# USCI_A1__SPI_Mode_2 register map
Vendor: Texas Instruments
Peripheral module from a debugger description file (folder msp430).
Registers are 8-bit, access not given, no defined reset value unless marked. A register's access mark holds for its fields unless they carry their own. Offsets are as the file gives them; lines under a group give offsets from that group; [hi:lo] are bit positions; {n}, {i} and the like mark numbered series; 'fields as' and 'values as' point back to an identical list; <NAME> marks a mode.

## USCI_A1_SPI_Mode
0x600 UCA1CTLW0__SPI 16-bit — USCI A1 Control Word Register 0
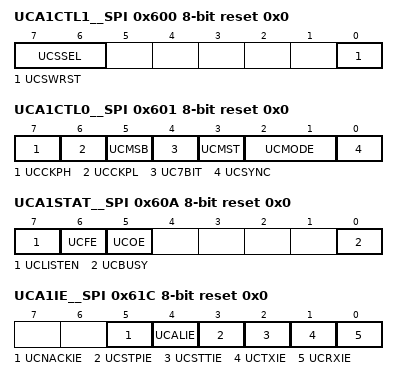
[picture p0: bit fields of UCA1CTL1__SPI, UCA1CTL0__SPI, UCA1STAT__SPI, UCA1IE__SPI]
0x600 UCA1CTL1__SPI rw reset 0x0 — USCI A1 Control Register 1
  [7:6] UCSSEL — USCI 1 Clock Source Select 1
    {v}=USCI 0 Clock Source: {v} (v=0..3)
  [0] UCSWRST — USCI Software Reset
0x601 UCA1CTL0__SPI rw reset 0x0 — USCI A1 Control Register 0
  [7] UCCKPH — Sync. Mode: Clock Phase
  [6] UCCKPL — Sync. Mode: Clock Polarity
  [5] UCMSB — Sync. Mode: MSB first 0:LSB / 1:MSB
  [4] UC7BIT — Sync. Mode: Data Bits 0:8-bits / 1:7-bits
  [3] UCMST — Sync. Mode: Master Select
  [2:1] UCMODE — Sync. Mode: USCI Mode 1
    {v}=Sync. Mode: USCI Mode: {v} (v=0..3)
  [0] UCSYNC — Sync-Mode 0:UART-Mode / 1:SPI-Mode
0x606 UCA1BRW__SPI 16-bit — USCI A1 Baud Word Rate 0
0x606 UCA1BR0__SPI — USCI A1 Baud Rate 0
0x607 UCA1BR1__SPI — USCI A1 Baud Rate 1
0x608 UCA1MCTL__SPI — USCI A1 Modulation Control
0x60A UCA1STAT__SPI rw reset 0x0 — USCI A1 Status Register
  [7] UCLISTEN — USCI Listen mode
  [6] UCFE — USCI Frame Error Flag
  [5] UCOE — USCI Overrun Error Flag
  [0] UCBUSY — USCI Busy Flag
0x60C UCA1RXBUF__SPI — USCI A1 Receive Buffer
0x60E UCA1TXBUF__SPI — USCI A1 Transmit Buffer
0x61C UCA1ICTL__SPI 16-bit — USCI A1 Interrupt Enable Register
0x61C UCA1IE__SPI rw reset 0x0 — USCI A1 Interrupt Enable Register
  [5] UCNACKIE — NACK Condition interrupt enable
  [4] UCALIE — Arbitration Lost interrupt enable
  [3] UCSTPIE — STOP Condition interrupt enable
  [2] UCSTTIE — START Condition interrupt enable
  [1] UCTXIE — USCI Transmit Interrupt Enable
  [0] UCRXIE — USCI Receive Interrupt Enable
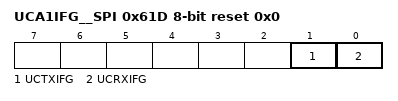
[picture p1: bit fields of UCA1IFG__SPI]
0x61D UCA1IFG__SPI rw reset 0x0 — USCI A1 Interrupt Flags Register
  [1] UCTXIFG — USCI Transmit Interrupt Flag
  [0] UCRXIFG — USCI Receive Interrupt Flag
0x61E UCA1IV__SPI 16-bit — USCI A1 Interrupt Vector Register
